AUTOSAR XML (schema 00048)
package /AdaptiveApplicationSwComponents
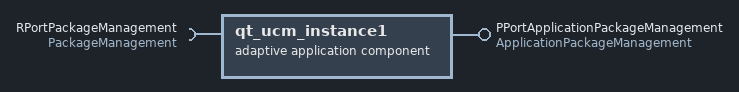
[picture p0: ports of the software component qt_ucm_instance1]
  adaptive application sw component type qt_ucm_instance1: category=APPLICATION_LEVEL
    provide port PPortApplicationPackageManagement: provided-interface=ApplicationPackageManagement
    require port RPortPackageManagement: required-interface=PackageManagement
package /Executables
  executable qt_ucm_instance1
    root sw component prototype rootSwComponentPrototype: application-type=qt_ucm_instance1
package /ProcessDesigns
  process design qt_ucm_instance1: executable=qt_ucm_instance1
package /SoftwareClusters
  software cluster SoftwareClusterPlatformCore: category=PLATFORM_CORE, contained-process=[package_manager, qt_crypto_instance1, qt_ucm_updateadapter, qt_ucm_instance1, qt_statemanager, qt_cm_instance1, ara_someip_routing_daemon, ara_dlt_daemon, phm_core, crypto_core, qt_phm_instance1, qt_phm_instance2, statemanager], design=SoftwareClusterDesign, type-approval=None
package /SoftwareClusterDesign
  software cluster design SoftwareClusterDesign
